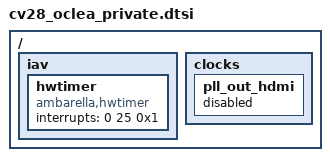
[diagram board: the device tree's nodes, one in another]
/ {
 iav {
  hwtimer {
   compatible = "ambarella,hwtimer";
   interrupts = <0 25 0x1>;
   interrupt-names = "hwtimer";
  };
 };
 clocks {
  pll_out_hdmi: pll_out_hdmi {
   status = "disabled";
  };
 };
};
